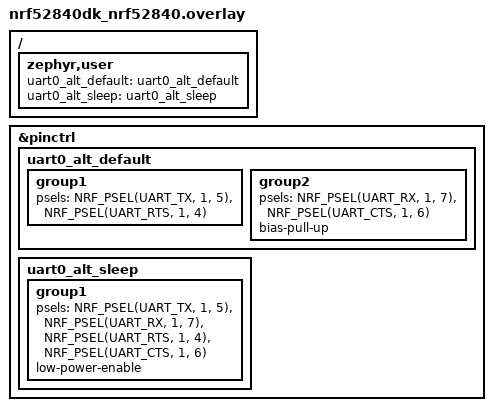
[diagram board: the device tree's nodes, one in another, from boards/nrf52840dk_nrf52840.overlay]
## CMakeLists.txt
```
# SPDX-License-Identifier: Apache-2.0

cmake_minimum_required(VERSION 3.20.0)

find_package(Zephyr REQUIRED HINTS $ENV{ZEPHYR_BASE})
project(dynamic_pinctrl)

target_sources(app PRIVATE src/main.c src/remap.c)
```

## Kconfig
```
# Copyright (c) 2021 Nordic Semiconductor ASA
# SPDX-License-Identifier: Apache-2.0

mainmenu "Dynamic pin control sample"

config REMAP_INIT_PRIORITY
	int "Remap routine initialization priority"
	default 50
	help
	  Initialization priority of the remap routine within the PRE_KERNEL1 level.
	  This priority must be greater than GPIO_INIT_PRIORITY and lower than
	  UART_INIT_PRIORITY.

source "Kconfig.zephyr"
```

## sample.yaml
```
sample:
  description: A dynamic pin control sample for nRF board/s.
  name: dynamic_pinctrl
tests:
  sample.boards.nrf.dynamic_pinctrl:
    build_only: true
    platform_allow: nrf52840dk/nrf52840
    integration_platforms:
      - nrf52840dk/nrf52840
```

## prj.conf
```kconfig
CONFIG_PINCTRL=y
CONFIG_PINCTRL_DYNAMIC=y
# configure serial and console to come after remap hook
CONFIG_SERIAL_INIT_PRIORITY=60
CONFIG_CONSOLE_INIT_PRIORITY=70
```

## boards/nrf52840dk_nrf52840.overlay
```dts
/*
 * Copyright (c) 2021 Nordic Semiconductor ASA
 * SPDX-License-Identifier: Apache-2.0
 */

/ {
	zephyr,user {
		uart0_alt_default = <&uart0_alt_default>;
		uart0_alt_sleep = <&uart0_alt_sleep>;
	};
};

&pinctrl {
	/* Alternative pin configuration for UART0 */
	uart0_alt_default: uart0_alt_default {
		group1 {
			psels = <NRF_PSEL(UART_TX, 1, 5)>,
				<NRF_PSEL(UART_RTS, 1, 4)>;
		};
		group2 {
			psels = <NRF_PSEL(UART_RX, 1, 7)>,
				<NRF_PSEL(UART_CTS, 1, 6)>;
			bias-pull-up;
		};
	};

	uart0_alt_sleep: uart0_alt_sleep {
		group1 {
			psels = <NRF_PSEL(UART_TX, 1, 5)>,
				<NRF_PSEL(UART_RX, 1, 7)>,
				<NRF_PSEL(UART_RTS, 1, 4)>,
				<NRF_PSEL(UART_CTS, 1, 6)>;
			low-power-enable;
		};
	};
};
```

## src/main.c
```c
/*
 * Copyright (c) 2021 Nordic Semiconductor ASA
 *
 * SPDX-License-Identifier: Apache-2.0
 */

#include <zephyr/sys/printk.h>

int main(void)
{
	printk("Hello World!\n");
	return 0;
}
```

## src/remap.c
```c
/*
 * Copyright (c) 2021 Nordic Semiconductor ASA
 *
 * SPDX-License-Identifier: Apache-2.0
 */

#include <zephyr/init.h>
#include <zephyr/drivers/gpio.h>
#include <zephyr/drivers/pinctrl.h>

/* make sure devices and remap hook are initialized in the correct order */
BUILD_ASSERT((CONFIG_GPIO_INIT_PRIORITY < CONFIG_REMAP_INIT_PRIORITY) &&
	     (CONFIG_REMAP_INIT_PRIORITY < CONFIG_SERIAL_INIT_PRIORITY),
	     "Device driver priorities are not set correctly");

PINCTRL_DT_DEV_CONFIG_DECLARE(DT_NODELABEL(uart0));

/* UART0 alternative configurations (default and sleep states) */
PINCTRL_DT_STATE_PINS_DEFINE(DT_PATH(zephyr_user), uart0_alt_default);
#ifdef CONFIG_PM_DEVICE
PINCTRL_DT_STATE_PINS_DEFINE(DT_PATH(zephyr_user), uart0_alt_sleep);
#endif

static const struct pinctrl_state uart0_alt[] = {
	PINCTRL_DT_STATE_INIT(uart0_alt_default, PINCTRL_STATE_DEFAULT),
#ifdef CONFIG_PM_DEVICE
	PINCTRL_DT_STATE_INIT(uart0_alt_sleep, PINCTRL_STATE_SLEEP),
#endif
};

static int remap_pins(void)
{
	int ret;
	const struct gpio_dt_spec button = GPIO_DT_SPEC_GET_OR(DT_ALIAS(sw0),
							       gpios, {0});


	if (!gpio_is_ready_dt(&button)) {
		return -ENODEV;
	}

	ret = gpio_pin_configure_dt(&button, GPIO_INPUT);
	if (ret < 0) {
		return ret;
	}

	/* remap UART0 pins if button is pressed */
	if (gpio_pin_get_dt(&button)) {
		struct pinctrl_dev_config *uart0_config =
			PINCTRL_DT_DEV_CONFIG_GET(DT_NODELABEL(uart0));

		return pinctrl_update_states(uart0_config, uart0_alt,
					     ARRAY_SIZE(uart0_alt));

	}

	return 0;
}

SYS_INIT(remap_pins, PRE_KERNEL_1, CONFIG_REMAP_INIT_PRIORITY);
```
